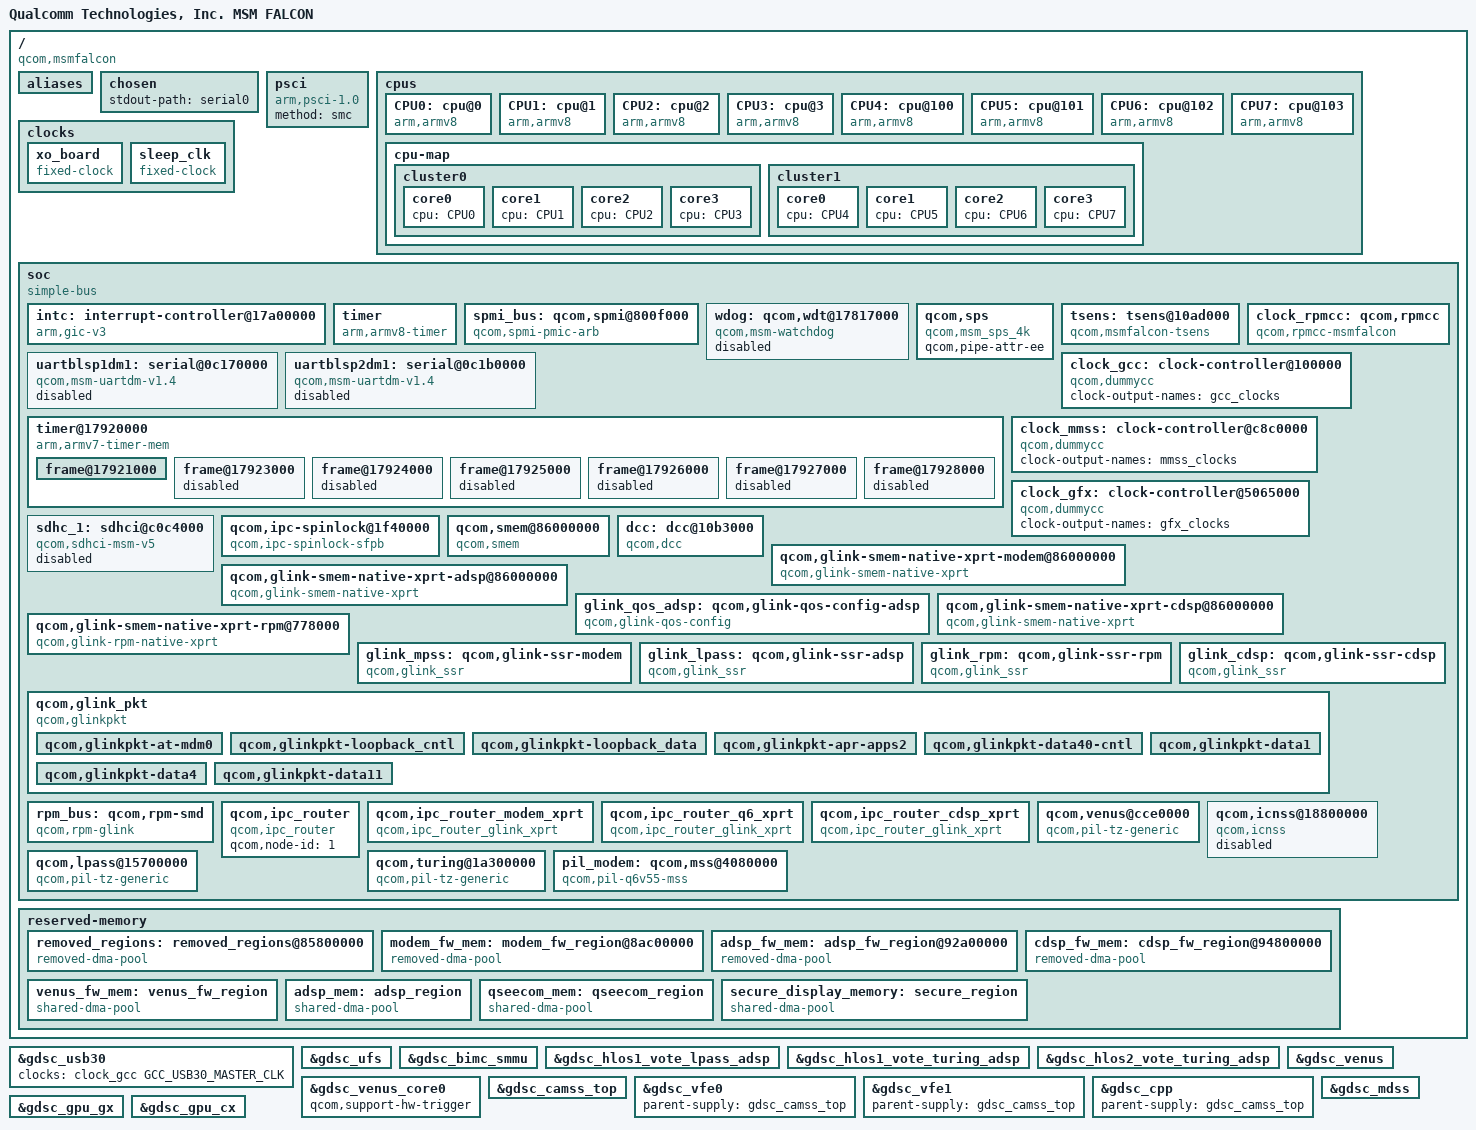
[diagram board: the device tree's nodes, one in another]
/* Copyright (c) 2016, The Linux Foundation. All rights reserved.
 *
 * This program is free software; you can redistribute it and/or modify
 * it under the terms of the GNU General Public License version 2 and
 * only version 2 as published by the Free Software Foundation.
 *
 * This program is distributed in the hope that it will be useful,
 * but WITHOUT ANY WARRANTY; without even the implied warranty of
 * MERCHANTABILITY or FITNESS FOR A PARTICULAR PURPOSE.  See the
 * GNU General Public License for more details.
 */

#include "skeleton64.dtsi"
#include <dt-bindings/clock/qcom,gcc-msmfalcon.h>
#include <dt-bindings/clock/qcom,gpu-msmfalcon.h>
#include <dt-bindings/clock/qcom,mmcc-msmfalcon.h>
#include <dt-bindings/clock/qcom,rpmcc.h>
#include <dt-bindings/interrupt-controller/arm-gic.h>
#include <dt-bindings/regulator/qcom,rpm-smd-regulator.h>

/ {
	model = "Qualcomm Technologies, Inc. MSM FALCON";
	compatible = "qcom,msmfalcon";
	qcom,msm-id = <317 0x0>;
	interrupt-parent = <&intc>;

	aliases {
		serial0 = &uartblsp1dm1;
		sdhc1 = &sdhc_1; /* SDC1 eMMC slot */
	};

	chosen {
		stdout-path = "serial0";
	};

	psci {
		compatible = "arm,psci-1.0";
		method = "smc";
	};

	cpus {
		#address-cells = <2>;
		#size-cells = <0>;

		CPU0: cpu@0 {
			device_type = "cpu";
			compatible = "arm,armv8";
			reg = <0x0 0x0>;
			enable-method = "psci";
		};

		CPU1: cpu@1 {
			device_type = "cpu";
			compatible = "arm,armv8";
			reg = <0x0 0x1>;
			enable-method = "psci";
		};

		CPU2: cpu@2 {
			device_type = "cpu";
			compatible = "arm,armv8";
			reg = <0x0 0x2>;
			enable-method = "psci";
		};

		CPU3: cpu@3 {
			device_type = "cpu";
			compatible = "arm,armv8";
			reg = <0x0 0x3>;
			enable-method = "psci";
		};

		CPU4: cpu@100 {
			device_type = "cpu";
			compatible = "arm,armv8";
			reg = <0x0 0x100>;
			enable-method = "psci";
		};

		CPU5: cpu@101 {
			device_type = "cpu";
			compatible = "arm,armv8";
			reg = <0x0 0x101>;
			enable-method = "psci";
		};

		CPU6: cpu@102 {
			device_type = "cpu";
			compatible = "arm,armv8";
			reg = <0x0 0x102>;
			enable-method = "psci";
		};

		CPU7: cpu@103 {
			device_type = "cpu";
			compatible = "arm,armv8";
			reg = <0x0 0x103>;
			enable-method = "psci";
		};

		cpu-map {
			cluster0 {
				core0 {
					cpu = <&CPU0>;
				};

				core1 {
					cpu = <&CPU1>;
				};

				core2 {
					cpu = <&CPU2>;
				};

				core3 {
					cpu = <&CPU3>;
				};
			};

			cluster1 {
				core0 {
					cpu = <&CPU4>;
				};

				core1 {
					cpu = <&CPU5>;
				};

				core2 {
					cpu = <&CPU6>;
				};

				core3 {
					cpu = <&CPU7>;
				};
			};
		};
	};

	clocks {
		xo_board {
			compatible = "fixed-clock";
			#clock-cells = <0>;
			clock-frequency = <19200000>;
			clock-output-names = "xo_board";
		};

		sleep_clk {
			compatible = "fixed-clock";
			#clock-cells = <0>;
			clock-frequency = <32764>;
			clock-output-names = "sleep_clk";
		};
	};

	soc: soc { };

	reserved-memory {
		#address-cells = <2>;
		#size-cells = <2>;
		ranges;

		removed_regions: removed_regions@85800000 {
			compatible = "removed-dma-pool";
			no-map;
			reg = <0x0 0x85800000 0x0 0x3700000>;
		};

		modem_fw_mem: modem_fw_region@8ac00000 {
			compatible = "removed-dma-pool";
			no-map;
			reg = <0x0 0x8ac00000 0x0 0x7e00000>;
		};

		adsp_fw_mem: adsp_fw_region@92a00000 {
			compatible = "removed-dma-pool";
			no-map;
			reg = <0x0 0x92a00000 0x0 0x1e00000>;
		};

		cdsp_fw_mem: cdsp_fw_region@94800000 {
			compatible = "removed-dma-pool";
			no-map;
			reg = <0x0 0x94800000 0x0 0x600000>;
		};

		venus_fw_mem: venus_fw_region {
			compatible = "shared-dma-pool";
			alloc-ranges = <0x0 0x80000000 0x0 0x20000000>;
			reusable;
			alignment = <0x0 0x400000>;
			size = <0x0 0x800000>;
		};

		adsp_mem: adsp_region {
			compatible = "shared-dma-pool";
			alloc-ranges = <0x0 0x00000000 0x0 0xffffffff>;
			reusable;
			alignment = <0x0 0x400000>;
			size = <0x0 0x400000>;
		};

		qseecom_mem: qseecom_region {
			compatible = "shared-dma-pool";
			alloc-ranges = <0x0 0x00000000 0x0 0xffffffff>;
			reusable;
			alignment = <0x0 0x400000>;
			size = <0x0 0x1400000>;
		};

		secure_display_memory: secure_region {
			compatible = "shared-dma-pool";
			alloc-ranges = <0x0 0x00000000 0x0 0xffffffff>;
			reusable;
			alignment = <0x0 0x400000>;
			size = <0x0 0x5c00000>;
		};
	};
};

#include "msmfalcon-smp2p.dtsi"
#include "msmfalcon-coresight.dtsi"
&soc {
	#address-cells = <1>;
	#size-cells = <1>;
	ranges = <0 0 0 0xffffffff>;
	compatible = "simple-bus";

	intc: interrupt-controller@17a00000 {
		compatible = "arm,gic-v3";
		reg = <0x17a00000 0x10000>,       /* GICD */
		      <0x17b00000 0x100000>;      /* GICR * 8 */
		#interrupt-cells = <3>;
		#address-cells = <1>;
		#size-cells = <1>;
		ranges;
		interrupt-controller;
		#redistributor-regions = <1>;
		redistributor-stride = <0x0 0x20000>;
		interrupts = <1 9 4>;
	};

	timer {
		compatible = "arm,armv8-timer";
		interrupts = <1 1 0xf08>,
			     <1 2 0xf08>,
			     <1 3 0xf08>,
			     <1 0 0xf08>;
		clock-frequency = <19200000>;
	};

	spmi_bus: qcom,spmi@800f000 {
		compatible = "qcom,spmi-pmic-arb";
		reg = <0x800f000 0x1000>,
			<0x8400000 0x1000000>,
			<0x9400000 0x1000000>,
			<0xa400000 0x220000>,
			<0x800a000 0x3000>;
		reg-names = "core", "chnls", "obsrvr", "intr", "cnfg";
		interrupt-names = "periph_irq";
		interrupts = <GIC_SPI 326 IRQ_TYPE_NONE>;
		qcom,ee = <0>;
		qcom,channel = <0>;
		#address-cells = <2>;
		#size-cells = <0>;
		interrupt-controller;
		#interrupt-cells = <4>;
		cell-index = <0>;
		qcom,not-wakeup; /* Needed until Full-boot-chain enabled */
		status = "ok";
	};

	wdog: qcom,wdt@17817000 {
		status = "disabled";
		compatible = "qcom,msm-watchdog";
		reg = <0x17817000 0x1000>;
		reg-names = "wdt-base";
		interrupts = <0 3 0>, <0 4 0>;
		qcom,bark-time = <11000>;
		qcom,pet-time = <10000>;
		qcom,ipi-ping;
		qcom,wakeup-enable;
	};

	qcom,sps {
		compatible = "qcom,msm_sps_4k";
		qcom,pipe-attr-ee;
	};

	tsens: tsens@10ad000 {
		compatible = "qcom,msmfalcon-tsens";
		reg = <0x10ad000 0x2000>,
			<0x784240 0x1000>;
		reg-names = "tsens_physical", "tsens_eeprom_physical";
		interrupts = <0 184 0>, <0 430 0>;
		interrupt-names = "tsens-upper-lower", "tsens-critical";
		qcom,sensors = <14>;
		qcom,slope = <3200 3200 3200 3200 3200 3200 3200 3200
					3200 3200 3200 3200 3200 3200>;
	};

	uartblsp1dm1: serial@0c170000 {
		compatible = "qcom,msm-uartdm-v1.4", "qcom,msm-uartdm";
		reg = <0xc170000 0x1000>;
		interrupts = <0 108 0>;
		status = "disabled";
		clocks = <&clock_gcc GCC_BLSP1_UART2_APPS_CLK>,
			 <&clock_gcc GCC_BLSP1_AHB_CLK>;
		clock-names = "core", "iface";
	};

	uartblsp2dm1: serial@0c1b0000 {
		compatible = "qcom,msm-uartdm-v1.4", "qcom,msm-uartdm";
		reg = <0xc1b0000 0x1000>;
		interrupts = <0 114 0>;
		status = "disabled";
		clocks = <&clock_gcc GCC_BLSP2_UART2_APPS_CLK>,
			 <&clock_gcc GCC_BLSP2_AHB_CLK>;
		clock-names = "core", "iface";
	};

	timer@17920000 {
		#address-cells = <1>;
		#size-cells = <1>;
		ranges;
		compatible = "arm,armv7-timer-mem";
		reg = <0x17920000 0x1000>;
		clock-frequency = <19200000>;

		frame@17921000 {
			frame-number = <0>;
			interrupts = <0 8 0x4>,
				     <0 7 0x4>;
			reg = <0x17921000 0x1000>,
			      <0x17922000 0x1000>;
		};

		frame@17923000 {
			frame-number = <1>;
			interrupts = <0 9 0x4>;
			reg = <0x17923000 0x1000>;
			status = "disabled";
		};

		frame@17924000 {
			frame-number = <2>;
			interrupts = <0 10 0x4>;
			reg = <0x17924000 0x1000>;
			status = "disabled";
		};

		frame@17925000 {
			frame-number = <3>;
			interrupts = <0 11 0x4>;
			reg = <0x17925000 0x1000>;
			status = "disabled";
		};

		frame@17926000 {
			frame-number = <4>;
			interrupts = <0 12 0x4>;
			reg = <0x17926000 0x1000>;
			status = "disabled";
		};

		frame@17927000 {
			frame-number = <5>;
			interrupts = <0 13 0x4>;
			reg = <0x17927000 0x1000>;
			status = "disabled";
		};

		frame@17928000 {
			frame-number = <6>;
			interrupts = <0 14 0x4>;
			reg = <0x17928000 0x1000>;
			status = "disabled";
		};
	};

	clock_rpmcc: qcom,rpmcc {
		compatible = "qcom,rpmcc-msmfalcon", "qcom,rpmcc";
		#clock-cells = <1>;
	};

	clock_gcc: clock-controller@100000 {
		compatible = "qcom,dummycc";
		clock-output-names = "gcc_clocks";
		#clock-cells = <1>;
		#reset-cells = <1>;
	};

	clock_mmss: clock-controller@c8c0000 {
		compatible = "qcom,dummycc";
		clock-output-names = "mmss_clocks";
		#clock-cells = <1>;
		#reset-cells = <1>;
	};

	clock_gfx: clock-controller@5065000 {
		compatible = "qcom,dummycc";
		clock-output-names = "gfx_clocks";
		#clock-cells = <1>;
		#reset-cells = <1>;
	};

	sdhc_1: sdhci@c0c4000 {
		compatible = "qcom,sdhci-msm-v5";
		reg = <0xc0c4000 0x1000>, <0xc0c5000 0x1000>;
		reg-names = "hc_mem", "cmdq_mem";

		interrupts = <0 129 0>, <0 227 0>;
		interrupt-names = "hc_irq", "pwr_irq";

		qcom,bus-width = <8>;
		qcom,large-address-bus;

		qcom,devfreq,freq-table = <50000000 200000000>;

		clocks = <&clock_gcc GCC_SDCC1_AHB_CLK>,
			 <&clock_gcc GCC_SDCC1_APPS_CLK>;
		clock-names = "iface_clk", "core_clk";

		status = "disabled";
	};

	qcom,ipc-spinlock@1f40000 {
		compatible = "qcom,ipc-spinlock-sfpb";
		reg = <0x1f40000 0x8000>;
		qcom,num-locks = <8>;
	};

	qcom,smem@86000000 {
		compatible = "qcom,smem";
		reg = <0x86000000 0x200000>,
			<0x17911008 0x4>,
			<0x778000 0x7000>,
			<0x1fd4000 0x8>;
		reg-names = "smem", "irq-reg-base", "aux-mem1",
			"smem_targ_info_reg";
		qcom,mpu-enabled;
	};

	dcc: dcc@10b3000 {
		compatible = "qcom,dcc";
		reg = <0x10b3000 0x1000>,
		      <0x10b4000 0x800>;
		reg-names = "dcc-base", "dcc-ram-base";

		clocks = <&clock_rpmcc RPM_QDSS_CLK>;
		clock-names = "dcc_clk";
	};

	qcom,glink-smem-native-xprt-modem@86000000 {
		compatible = "qcom,glink-smem-native-xprt";
		reg = <0x86000000 0x200000>,
			<0x17911008 0x4>;
		reg-names = "smem", "irq-reg-base";
		qcom,irq-mask = <0x8000>;
		interrupts = <0 452 1>;
		label = "mpss";
	};

	qcom,glink-smem-native-xprt-adsp@86000000 {
		compatible = "qcom,glink-smem-native-xprt";
		reg = <0x86000000 0x200000>,
			<0x17911008 0x4>;
		reg-names = "smem", "irq-reg-base";
		qcom,irq-mask = <0x200>;
		interrupts = <0 157 1>;
		label = "lpass";
		qcom,qos-config = <&glink_qos_adsp>;
		qcom,ramp-time = <0xaf>;
	};

	glink_qos_adsp: qcom,glink-qos-config-adsp {
		compatible = "qcom,glink-qos-config";
		qcom,flow-info = <0x3c 0x0>,
				<0x3c 0x0>,
				<0x3c 0x0>,
				<0x3c 0x0>;
		qcom,mtu-size = <0x800>;
		qcom,tput-stats-cycle = <0xa>;
	};

	qcom,glink-smem-native-xprt-cdsp@86000000 {
		compatible = "qcom,glink-smem-native-xprt";
		reg = <0x86000000 0x200000>,
			<0x17911008 0x4>;
		reg-names = "smem", "irq-reg-base";
		qcom,irq-mask = <0x20000000>;
		interrupts = <0 513 1>;
		label = "cdsp";
	};

	qcom,glink-smem-native-xprt-rpm@778000 {
		compatible = "qcom,glink-rpm-native-xprt";
		reg = <0x778000 0x7000>,
			<0x17911008 0x4>;
		reg-names = "msgram", "irq-reg-base";
		qcom,irq-mask = <0x1>;
		interrupts = <0 168 1>;
		label = "rpm";
	};

	glink_mpss: qcom,glink-ssr-modem {
		compatible = "qcom,glink_ssr";
		label = "modem";
		qcom,edge = "mpss";
		qcom,notify-edges = <&glink_lpass>, <&glink_rpm>,
				<&glink_cdsp>;
		qcom,xprt = "smem";
	};

	glink_lpass: qcom,glink-ssr-adsp {
		compatible = "qcom,glink_ssr";
		label = "adsp";
		qcom,edge = "lpass";
		qcom,notify-edges = <&glink_mpss>, <&glink_rpm>,
				<&glink_cdsp>;
		qcom,xprt = "smem";
	};

	glink_rpm: qcom,glink-ssr-rpm {
		compatible = "qcom,glink_ssr";
		label = "rpm";
		qcom,edge = "rpm";
		qcom,notify-edges = <&glink_lpass>, <&glink_mpss>,
				<&glink_cdsp>;
		qcom,xprt = "smem";
	};

	glink_cdsp: qcom,glink-ssr-cdsp {
		compatible = "qcom,glink_ssr";
		label = "cdsp";
		qcom,edge = "cdsp";
		qcom,notify-edges = <&glink_lpass>, <&glink_mpss>,
				<&glink_rpm>;
		qcom,xprt = "smem";
	};

	qcom,glink_pkt {
		compatible = "qcom,glinkpkt";

		qcom,glinkpkt-at-mdm0 {
			qcom,glinkpkt-transport = "smem";
			qcom,glinkpkt-edge = "mpss";
			qcom,glinkpkt-ch-name = "DS";
			qcom,glinkpkt-dev-name = "at_mdm0";
		};

		qcom,glinkpkt-loopback_cntl {
			qcom,glinkpkt-transport = "lloop";
			qcom,glinkpkt-edge = "local";
			qcom,glinkpkt-ch-name = "LOCAL_LOOPBACK_CLNT";
			qcom,glinkpkt-dev-name = "glink_pkt_loopback_ctrl";
		};

		qcom,glinkpkt-loopback_data {
			qcom,glinkpkt-transport = "lloop";
			qcom,glinkpkt-edge = "local";
			qcom,glinkpkt-ch-name = "glink_pkt_lloop_CLNT";
			qcom,glinkpkt-dev-name = "glink_pkt_loopback";
		};

		qcom,glinkpkt-apr-apps2 {
			qcom,glinkpkt-transport = "smem";
			qcom,glinkpkt-edge = "adsp";
			qcom,glinkpkt-ch-name = "apr_apps2";
			qcom,glinkpkt-dev-name = "apr_apps2";
		};

		qcom,glinkpkt-data40-cntl {
			qcom,glinkpkt-transport = "smem";
			qcom,glinkpkt-edge = "mpss";
			qcom,glinkpkt-ch-name = "DATA40_CNTL";
			qcom,glinkpkt-dev-name = "smdcntl8";
		};

		qcom,glinkpkt-data1 {
			qcom,glinkpkt-transport = "smem";
			qcom,glinkpkt-edge = "mpss";
			qcom,glinkpkt-ch-name = "DATA1";
			qcom,glinkpkt-dev-name = "smd7";
		};

		qcom,glinkpkt-data4 {
			qcom,glinkpkt-transport = "smem";
			qcom,glinkpkt-edge = "mpss";
			qcom,glinkpkt-ch-name = "DATA4";
			qcom,glinkpkt-dev-name = "smd8";
		};

		qcom,glinkpkt-data11 {
			qcom,glinkpkt-transport = "smem";
			qcom,glinkpkt-edge = "mpss";
			qcom,glinkpkt-ch-name = "DATA11";
			qcom,glinkpkt-dev-name = "smd11";
		};
	};

	rpm_bus: qcom,rpm-smd {
		compatible = "qcom,rpm-glink";
		qcom,glink-edge = "rpm";
		rpm-channel-name = "rpm_requests";
		rpm-standalone; /* TODO: remove this after bring up */
	};

	qcom,ipc_router {
		compatible = "qcom,ipc_router";
		qcom,node-id = <1>;
	};

	qcom,ipc_router_modem_xprt {
		compatible = "qcom,ipc_router_glink_xprt";
		qcom,ch-name = "IPCRTR";
		qcom,xprt-remote = "mpss";
		qcom,glink-xprt = "smem";
		qcom,xprt-linkid = <1>;
		qcom,xprt-version = <1>;
		qcom,fragmented-data;
	};

	qcom,ipc_router_q6_xprt {
		compatible = "qcom,ipc_router_glink_xprt";
		qcom,ch-name = "IPCRTR";
		qcom,xprt-remote = "lpass";
		qcom,glink-xprt = "smem";
		qcom,xprt-linkid = <1>;
		qcom,xprt-version = <1>;
		qcom,fragmented-data;
	};

	qcom,ipc_router_cdsp_xprt {
		compatible = "qcom,ipc_router_glink_xprt";
		qcom,ch-name = "IPCRTR";
		qcom,xprt-remote = "cdsp";
		qcom,glink-xprt = "smem";
		qcom,xprt-linkid = <1>;
		qcom,xprt-version = <1>;
		qcom,fragmented-data;
	};

	qcom,venus@cce0000 {
		compatible = "qcom,pil-tz-generic";
		reg = <0xcce0000 0x4000>;

		vdd-supply = <&gdsc_venus>;
		qcom,proxy-reg-names = "vdd";

		clocks = <&clock_mmss MMSS_VIDEO_CORE_CLK>,
			<&clock_mmss MMSS_VIDEO_AHB_CLK>,
			<&clock_mmss MMSS_VIDEO_AXI_CLK>;
		clock-names = "core_clk","iface_clk",
			"bus_clk";
		qcom,proxy-clock-names = "core_clk",
			"iface_clk","bus_clk";

		qcom,msm-bus,name = "pil-venus";
		qcom,msm-bus,num-cases = <2>;
		qcom,msm-bus,num-paths = <1>;
		qcom,msm-bus,vectors-KBps =
				<63 512 0 0>,
				<63 512 0 304000>;

		qcom,pas-id = <9>;
		qcom,proxy-timeout-ms = <100>;
		qcom,firmware-name = "venus";
		memory-region = <&venus_fw_mem>;
		status = "ok";
	};

	qcom,icnss@18800000 {
		status = "disabled";
		compatible = "qcom,icnss";
		reg = <0x18800000 0x800000>,
		      <0x10ac000 0x20>;
		reg-names = "membase", "mpm_config";
		interrupts = <0 413 0>,   /* CE0 */
			     <0 414 0>,   /* CE1 */
			     <0 415 0>,   /* CE2 */
			     <0 416 0>,   /* CE3 */
			     <0 417 0>,   /* CE4 */
			     <0 418 0>,   /* CE5 */
			     <0 420 0>,   /* CE6 */
			     <0 421 0>,   /* CE7 */
			     <0 422 0>,   /* CE8 */
			     <0 423 0>,   /* CE9 */
			     <0 424 0>,   /* CE10 */
			     <0 425 0>;   /* CE11 */
		qcom,wlan-msa-memory = <0x100000>;
	};

	qcom,lpass@15700000 {
		compatible = "qcom,pil-tz-generic";
		reg = <0x15700000 0x00100>;
		interrupts = <0 162 1>;

		vdd_cx-supply = <&pmfalcon_s3b_level>;
		qcom,proxy-reg-names = "vdd_cx";
		qcom,vdd_cx-uV-uA = <RPM_SMD_REGULATOR_LEVEL_TURBO 100000>;

		clocks = <&clock_rpmcc CXO_PIL_LPASS_CLK>;
		clock-names = "xo";
		qcom,proxy-clock-names = "xo";

		qcom,pas-id = <1>;
		qcom,proxy-timeout-ms = <10000>;
		qcom,smem-id = <423>;
		qcom,sysmon-id = <1>;
		qcom,ssctl-instance-id = <0x14>;
		qcom,firmware-name = "adsp";
		memory-region = <&adsp_fw_mem>;

		/* GPIO inputs from lpass */
		qcom,gpio-err-fatal = <&smp2pgpio_ssr_smp2p_2_in 0 0>;
		qcom,gpio-proxy-unvote = <&smp2pgpio_ssr_smp2p_2_in 2 0>;
		qcom,gpio-err-ready = <&smp2pgpio_ssr_smp2p_2_in 1 0>;
		qcom,gpio-stop-ack = <&smp2pgpio_ssr_smp2p_2_in 3 0>;

		/* GPIO output to lpass */
		qcom,gpio-force-stop = <&smp2pgpio_ssr_smp2p_2_out 0 0>;
		status = "ok";
	};

	qcom,turing@1a300000 {
		compatible = "qcom,pil-tz-generic";
		reg = <0x1a300000 0x00100>;
		interrupts = <0 518 1>;

		vdd_cx-supply = <&pmfalcon_s3b_level>;
		qcom,proxy-reg-names = "vdd_cx";
		qcom,vdd_cx-uV-uA = <RPM_SMD_REGULATOR_LEVEL_TURBO 100000>;

		clocks = <&clock_rpmcc CXO_PIL_CDSP_CLK>;
		clock-names = "xo";
		qcom,proxy-clock-names = "xo";

		qcom,pas-id = <18>;
		qcom,proxy-timeout-ms = <10000>;
		qcom,smem-id = <423>;
		qcom,sysmon-id = <7>;
		qcom,ssctl-instance-id = <0x17>;
		qcom,firmware-name = "cdsp";
		memory-region = <&cdsp_fw_mem>;

		/* GPIO inputs from turing */
		qcom,gpio-err-fatal = <&smp2pgpio_ssr_smp2p_5_in 0 0>;
		qcom,gpio-proxy-unvote = <&smp2pgpio_ssr_smp2p_5_in 2 0>;
		qcom,gpio-err-ready = <&smp2pgpio_ssr_smp2p_5_in 1 0>;
		qcom,gpio-stop-ack = <&smp2pgpio_ssr_smp2p_5_in 3 0>;

		/* GPIO output to turing*/
		qcom,gpio-force-stop = <&smp2pgpio_ssr_smp2p_5_out 0 0>;
		status = "ok";
	};

	pil_modem: qcom,mss@4080000 {
		compatible = "qcom,pil-q6v55-mss";
		reg = <0x4080000 0x100>,
		      <0x1f63000 0x008>,
		      <0x1f65000 0x008>,
		      <0x1f64000 0x008>,
		      <0x4180000 0x040>,
		      <0x00179000 0x004>;
		reg-names = "qdsp6_base", "halt_q6", "halt_modem",
			    "halt_nc", "rmb_base", "restart_reg";

		clocks = <&clock_rpmcc RPM_XO_CLK_SRC>,
			 <&clock_gcc GCC_MSS_CFG_AHB_CLK>,
			 <&clock_gcc GCC_BIMC_MSS_Q6_AXI_CLK>,
			 <&clock_gcc GCC_BOOT_ROM_AHB_CLK>,
			 <&clock_gcc GPLL0_OUT_MSSCC>,
			 <&clock_gcc GCC_MSS_SNOC_AXI_CLK>,
			 <&clock_gcc GCC_MSS_MNOC_BIMC_AXI_CLK>,
			 <&clock_rpmcc RPM_QDSS_CLK>;
		clock-names = "xo", "iface_clk", "bus_clk",
			      "mem_clk", "gpll0_mss_clk", "snoc_axi_clk",
			      "mnoc_axi_clk", "qdss_clk";
		qcom,proxy-clock-names = "xo", "qdss_clk";
		qcom,active-clock-names = "iface_clk", "bus_clk", "mem_clk",
					 "gpll0_mss_clk", "snoc_axi_clk",
					 "mnoc_axi_clk";

		interrupts = <0 448 1>;
		vdd_cx-supply = <&pmfalcon_s3b_level>;
		vdd_cx-voltage = <RPM_SMD_REGULATOR_LEVEL_TURBO>;
		vdd_mx-supply = <&pmfalcon_s5b_level>;
		vdd_mx-uV = <RPM_SMD_REGULATOR_LEVEL_TURBO>;
		qcom,firmware-name = "modem";
		qcom,pil-self-auth;
		qcom,sysmon-id = <0>;
		qcom,ssctl-instance-id = <0x12>;
		qcom,override-acc;
		qcom,qdsp6v62-1-5;
		memory-region = <&modem_fw_mem>;
		qcom,mem-protect-id = <0xF>;

		/* GPIO inputs from mss */
		qcom,gpio-err-fatal = <&smp2pgpio_ssr_smp2p_1_in 0 0>;
		qcom,gpio-err-ready = <&smp2pgpio_ssr_smp2p_1_in 1 0>;
		qcom,gpio-proxy-unvote = <&smp2pgpio_ssr_smp2p_1_in 2 0>;
		qcom,gpio-stop-ack = <&smp2pgpio_ssr_smp2p_1_in 3 0>;
		qcom,gpio-shutdown-ack = <&smp2pgpio_ssr_smp2p_1_in 7 0>;

		/* GPIO output to mss */
		qcom,gpio-force-stop = <&smp2pgpio_ssr_smp2p_1_out 0 0>;
		status = "ok";
	};
};

#include "msmfalcon-ion.dtsi"
#include "msmfalcon-bus.dtsi"
#include "msmfalcon-regulator.dtsi"
#include "msm-gdsc-falcon.dtsi"

&gdsc_usb30 {
	clock-names = "core_clk";
	clocks = <&clock_gcc GCC_USB30_MASTER_CLK>;
	status = "ok";
};

&gdsc_ufs {
	status = "ok";
};

&gdsc_bimc_smmu {
	clock-names = "bus_clk";
	clocks = <&clock_mmss MMSS_BIMC_SMMU_AXI_CLK>;
	proxy-supply = <&gdsc_bimc_smmu>;
	qcom,proxy-consumer-enable;
	status = "ok";
};

&gdsc_hlos1_vote_lpass_adsp {
	status = "ok";
};

&gdsc_hlos1_vote_turing_adsp {
	status = "ok";
};

&gdsc_hlos2_vote_turing_adsp {
	status = "ok";
};

&gdsc_venus {
	status = "ok";
};

&gdsc_venus_core0 {
	qcom,support-hw-trigger;
	status = "ok";
};

&gdsc_camss_top {
	status = "ok";
};

&gdsc_vfe0 {
	parent-supply = <&gdsc_camss_top>;
	status = "ok";
};

&gdsc_vfe1 {
	parent-supply = <&gdsc_camss_top>;
	status = "ok";
};

&gdsc_cpp {
	parent-supply = <&gdsc_camss_top>;
	status = "ok";
};

&gdsc_mdss {
	clock-names = "bus_clk", "rot_clk";
	clocks = <&clock_mmss MMSS_MDSS_AXI_CLK>,
		 <&clock_mmss MMSS_MDSS_ROT_CLK>;
	proxy-supply = <&gdsc_mdss>;
	qcom,proxy-consumer-enable;
	status = "ok";
};

&gdsc_gpu_gx {
	clock-names = "bimc_core_clk", "core_clk", "core_root_clk";
	clocks = <&clock_gcc GCC_GPU_BIMC_GFX_CLK>,
		 <&clock_gfx GPUCC_GFX3D_CLK>,
		 <&clock_gfx GFX3D_CLK_SRC>;
	qcom,force-enable-root-clk;
	parent-supply = <&gfx_vreg_corner>;
	status = "ok";
};

&gdsc_gpu_cx {
	status = "ok";
};

#include "msm-pmfalcon.dtsi"
#include "msm-pm2falcon.dtsi"
#include "msm-arm-smmu-falcon.dtsi"
#include "msm-arm-smmu-impl-defs-falcon.dtsi"
